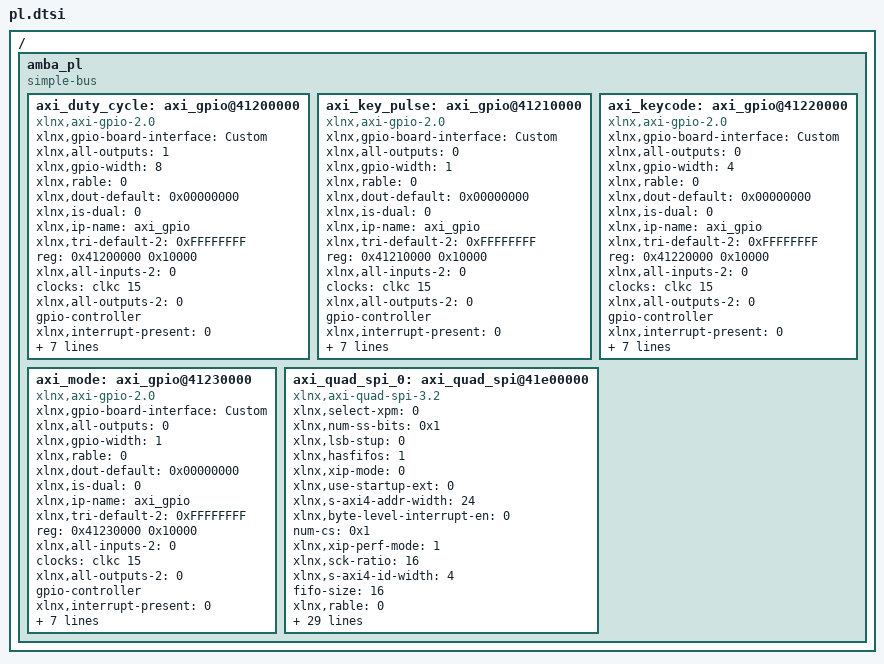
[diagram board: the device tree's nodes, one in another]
/ {
	amba_pl: amba_pl {
		ranges;
		compatible = "simple-bus";
		#address-cells = <1>;
		#size-cells = <1>;
		axi_duty_cycle: axi_gpio@41200000 {
			xlnx,gpio-board-interface = "Custom";
			compatible = "xlnx,axi-gpio-2.0" , "xlnx,xps-gpio-1.00.a";
			xlnx,all-outputs = <1>;
			#gpio-cells = <2>;
			xlnx,gpio-width = <8>;
			xlnx,rable = <0>;
			xlnx,dout-default = <0x00000000>;
			xlnx,is-dual = <0>;
			xlnx,ip-name = "axi_gpio";
			xlnx,tri-default-2 = <0xFFFFFFFF>;
			reg = <0x41200000 0x10000>;
			xlnx,all-inputs-2 = <0>;
			clocks = <&clkc 15>;
			xlnx,all-outputs-2 = <0>;
			gpio-controller;
			xlnx,interrupt-present = <0>;
			xlnx,gpio2-board-interface = "Custom";
			xlnx,edk-iptype = "PERIPHERAL";
			xlnx,dout-default-2 = <0x00000000>;
			xlnx,gpio2-width = <32>;
			status = "okay";
			clock-names = "s_axi_aclk";
			xlnx,tri-default = <0xFFFFFFFF>;
			xlnx,name = "axi_duty_cycle";
			xlnx,all-inputs = <0>;
		};
		axi_key_pulse: axi_gpio@41210000 {
			xlnx,gpio-board-interface = "Custom";
			compatible = "xlnx,axi-gpio-2.0" , "xlnx,xps-gpio-1.00.a";
			xlnx,all-outputs = <0>;
			#gpio-cells = <2>;
			xlnx,gpio-width = <1>;
			xlnx,rable = <0>;
			xlnx,dout-default = <0x00000000>;
			xlnx,is-dual = <0>;
			xlnx,ip-name = "axi_gpio";
			xlnx,tri-default-2 = <0xFFFFFFFF>;
			reg = <0x41210000 0x10000>;
			xlnx,all-inputs-2 = <0>;
			clocks = <&clkc 15>;
			xlnx,all-outputs-2 = <0>;
			gpio-controller;
			xlnx,interrupt-present = <0>;
			xlnx,gpio2-board-interface = "Custom";
			xlnx,edk-iptype = "PERIPHERAL";
			xlnx,dout-default-2 = <0x00000000>;
			xlnx,gpio2-width = <32>;
			status = "okay";
			clock-names = "s_axi_aclk";
			xlnx,tri-default = <0xFFFFFFFF>;
			xlnx,name = "axi_key_pulse";
			xlnx,all-inputs = <1>;
		};
		axi_keycode: axi_gpio@41220000 {
			xlnx,gpio-board-interface = "Custom";
			compatible = "xlnx,axi-gpio-2.0" , "xlnx,xps-gpio-1.00.a";
			xlnx,all-outputs = <0>;
			#gpio-cells = <2>;
			xlnx,gpio-width = <4>;
			xlnx,rable = <0>;
			xlnx,dout-default = <0x00000000>;
			xlnx,is-dual = <0>;
			xlnx,ip-name = "axi_gpio";
			xlnx,tri-default-2 = <0xFFFFFFFF>;
			reg = <0x41220000 0x10000>;
			xlnx,all-inputs-2 = <0>;
			clocks = <&clkc 15>;
			xlnx,all-outputs-2 = <0>;
			gpio-controller;
			xlnx,interrupt-present = <0>;
			xlnx,gpio2-board-interface = "Custom";
			xlnx,edk-iptype = "PERIPHERAL";
			xlnx,dout-default-2 = <0x00000000>;
			xlnx,gpio2-width = <32>;
			status = "okay";
			clock-names = "s_axi_aclk";
			xlnx,tri-default = <0xFFFFFFFF>;
			xlnx,name = "axi_keycode";
			xlnx,all-inputs = <1>;
		};
		axi_mode: axi_gpio@41230000 {
			xlnx,gpio-board-interface = "Custom";
			compatible = "xlnx,axi-gpio-2.0" , "xlnx,xps-gpio-1.00.a";
			xlnx,all-outputs = <0>;
			#gpio-cells = <2>;
			xlnx,gpio-width = <1>;
			xlnx,rable = <0>;
			xlnx,dout-default = <0x00000000>;
			xlnx,is-dual = <0>;
			xlnx,ip-name = "axi_gpio";
			xlnx,tri-default-2 = <0xFFFFFFFF>;
			reg = <0x41230000 0x10000>;
			xlnx,all-inputs-2 = <0>;
			clocks = <&clkc 15>;
			xlnx,all-outputs-2 = <0>;
			gpio-controller;
			xlnx,interrupt-present = <0>;
			xlnx,gpio2-board-interface = "Custom";
			xlnx,edk-iptype = "PERIPHERAL";
			xlnx,dout-default-2 = <0x00000000>;
			xlnx,gpio2-width = <32>;
			status = "okay";
			clock-names = "s_axi_aclk";
			xlnx,tri-default = <0xFFFFFFFF>;
			xlnx,name = "axi_mode";
			xlnx,all-inputs = <1>;
		};
		axi_quad_spi_0: axi_quad_spi@41e00000 {
			xlnx,select-xpm = <0>;
			xlnx,num-ss-bits = <0x1>;
			compatible = "xlnx,axi-quad-spi-3.2" , "xlnx,xps-spi-2.00.a";
			xlnx,lsb-stup = <0>;
			xlnx,hasfifos = <1>;
			xlnx,xip-mode = <0>;
			xlnx,use-startup-ext = <0>;
			xlnx,s-axi4-addr-width = <24>;
			xlnx,byte-level-interrupt-en = <0>;
			num-cs = <0x1>;
			xlnx,xip-perf-mode = <1>;
			xlnx,sck-ratio = <16>;
			xlnx,s-axi4-id-width = <4>;
			fifo-size = <16>;
			xlnx,rable = <0>;
			xlnx,multiples16 = <1>;
			xlnx,master-mode = <1>;
			xlnx,shared-startup = <0>;
			xlnx,ip-name = "axi_quad_spi";
			xlnx,qspi-board-interface = "Custom";
			xlnx,new-seq-en = <1>;
			reg = <0x41e00000 0x10000>;
			xlnx,dual-quad-mode = <0>;
			bits-per-word = <8>;
			clocks = <&clkc 15>, <&clkc 15>;
			xlnx,num-transfer-bits = <8>;
			xlnx,spi-memory = <1>;
			xlnx,s-axi4-data-width = <32>;
			xlnx,edk-iptype = "PERIPHERAL";
			xlnx,slaveonly = <0>;
			xlnx,use-startup-int = <0>;
			xlnx,use-startup = <0>;
			xlnx,type-of-axi4-interface = <0>;
			xlnx,async-clk = <0>;
			xlnx,spi-mode = <0>;
			xlnx,sck-ratio1 = <1>;
			status = "okay";
			xlnx,fifo-depth = <16>;
			clock-names = "ext_spi_clk" , "s_axi_aclk";
			xlnx,uc-family = <0>;
			xlnx,spi-mem-addr-bits = <24>;
			xlnx,axi-interface = <0>;
			xlnx,Axi4-address = <0>;
			xlnx,sub-family = "zynq";
			xlnx,name = "axi_quad_spi_0";
			xlnx,fifo-included = <1>;
		};
	};
};
